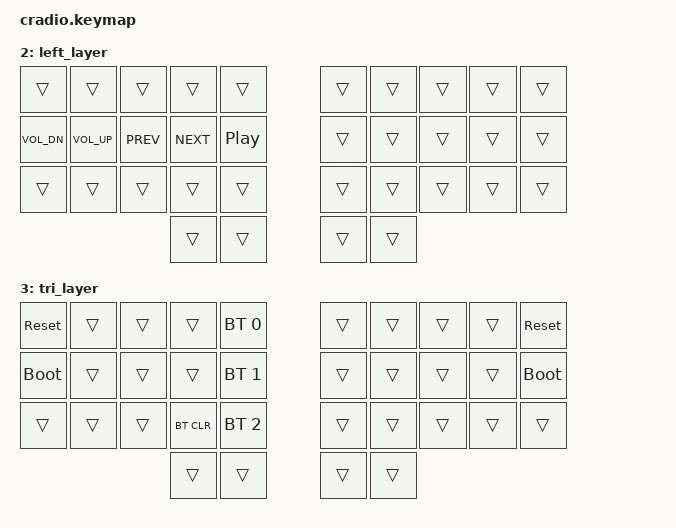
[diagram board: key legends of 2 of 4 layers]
// Copyright (c) 2022 The ZMK Contributors
// SPDX-License-Identifier: MIT

#include <behaviors.dtsi>
#include <dt-bindings/zmk/keys.h>
#include <dt-bindings/zmk/bt.h>

// Home row mods macro
#define HRML(k1,k2,k3,k4) &ht LSHFT k1  &ht LALT k2  &ht LCTRL k3  &ht LGUI k4
#define HRMR(k1,k2,k3,k4) &ht RGUI k1  &ht RCTRL k2  &ht RALT k3  &ht RSHFT k4

/ {
    behaviors {
        ht: hold_tap {
            compatible = "zmk,behavior-hold-tap";
            #binding-cells = <2>;
            flavor = "tap-preferred";
            tapping-term-ms = <200>;
            quick-tap-ms = <150>;
            require-prior-idle-ms = <100>;
            bindings = <&kp>, <&kp>;
        };
        gresc: grave_escape {
            compatible = "zmk,behavior-mod-morph";
            #binding-cells = <0>;
            bindings = <&kp ESC>, <&kp GRAVE>;
            mods = <(MOD_LGUI|MOD_LSFT|MOD_RGUI|MOD_RSFT)>;
            keep-mods = <(MOD_LGUI|MOD_RSFT)>;
        };
    };

    conditional_layers {
        compatible = "zmk,conditional-layers";
        tri_layer {
            if-layers = <1 2>;
            then-layer = <3>;
        };
    };

    keymap {
        compatible = "zmk,keymap";
        default_layer {
            bindings = <
        //╭──────────────┬──────────────┬──────────────┬──────────────┬──────────────╮   ╭──────────────┬──────────────┬──────────────┬──────────────┬──────────────╮
        //│      Q       │      W       │      E       │      R       │      T       │   │      Y       │      U       │      I       │      O       │      P       │
               &kp Q          &kp W          &kp E          &kp R          &kp T              &kp Y          &kp U          &kp I          &kp O          &kp P
        //├──────────────┼──────────────┼──────────────┼──────────────┼──────────────┤   ├──────────────┼──────────────┼──────────────┼──────────────┼──────────────┤
        //│      A       │      S       │      D       │      F       │      G       │   │      H       │      J       │      K       │      L       │       ;      │
            HRML(A,             S,             D,             F)           &kp G              &kp H       HRMR(J,             K,             L,            SEMI)
        //├──────────────┼──────────────┼──────────────┼──────────────┼──────────────┤   ├──────────────┼──────────────┼──────────────┼──────────────┼──────────────┤
        //│      Z       │      X       │      C       │      V       │      B       │   │      N       │      M       │     , <      │     . >      │     / ?      │
               &kp Z          &kp X          &kp C          &kp V         &kp B               &kp N          &kp M         &kp COMMA       &kp DOT       &kp FSLH
        //╰──────────────┴──────────────┴──────────────┼──────────────┼──────────────┤   ├──────────────┼──────────────┼──────────────┴──────────────┴──────────────╯
                                                            &gresc       &lt 1 TAB          &lt 2 SPACE      &kp RET 
        //                                             ╰──────────────┴──────────────╯   ╰──────────────┴──────────────╯
            >;
        };

        right_layer {
            bindings = <
        //╭──────────────┬──────────────┬──────────────┬──────────────┬──────────────╮   ╭──────────────┬──────────────┬──────────────┬──────────────┬──────────────╮
        //│       1      │      2       │       3      │      4       │      5       │   │      6       │       7      │       8      │       9      │      0       │
               &kp N1         &kp N2         &kp N3         &kp N4        &kp N5             &kp N6          &kp N7          &kp N8        &kp N9        &kp N0
        //├──────────────┼──────────────┼──────────────┼──────────────┼──────────────┤   ├──────────────┼──────────────┼──────────────┼──────────────┼──────────────┤
        //│     F2       │    F5        │    F9        │     F10      │    F12       │   │     LEFT     │     DOWN     │      UP      │     RIGHT    │     ' "      │
           HRML(F2,           F5,            F9,             F10)        &kp F12             &kp LEFT       &kp DOWN        &kp UP        &kp RIGHT    &ht RSHFT SQT
        //├──────────────┼──────────────┼──────────────┼──────────────┼──────────────┤   ├──────────────┼──────────────┼──────────────┼──────────────┼──────────────┤
        //│    GRAVE     │  Screenshot  │   Screenshot │     CAPS     │    DEL       │   │       {      │       }      │       -      │       =      │       \      │
             &kp GRAVE    &kp LG(LS(N5)) &kp LG(LS(N4))   &caps_word     &kp DEL             &kp LBKT       &kp RBKT      &kp MINUS        &kp EQUAL      &kp BSLH
        //╰──────────────┴──────────────┴──────────────┼──────────────┼──────────────┤   ├──────────────┼──────────────┼──────────────┴──────────────┴──────────────╯
                                                            &trans         &trans            &kp BSPC        &trans
        //                                             ╰──────────────┴──────────────╯   ╰──────────────┴──────────────╯
            >;
        };

        left_layer {
            bindings = <
        //╭──────────────┬──────────────┬──────────────┬──────────────┬──────────────╮   ╭──────────────┬──────────────┬──────────────┬──────────────┬──────────────╮
        //│              │              │              │              │              │   │              │              │              │              │              │
                &trans       &trans          &trans         &trans         &trans             &trans         &trans          &trans         &trans        &trans
        //├──────────────┼──────────────┼──────────────┼──────────────┼──────────────┤   ├──────────────┼──────────────┼──────────────┼──────────────┼──────────────┤
        //│              │              │              │              │              │   │              │              │              │              │              │
            &kp C_VOL_DN   &kp C_VOL_UP    &kp C_PREV     &kp C_NEXT      &kp C_PP            &trans         &trans          &trans         &trans        &trans
        //├──────────────┼──────────────┼──────────────┼──────────────┼──────────────┤   ├──────────────┼──────────────┼──────────────┼──────────────┼──────────────┤
        //│              │              │              │              │              │   │              │              │              │              │              │
               &trans         &trans         &trans         &trans         &trans             &trans         &trans          &trans         &trans        &trans
        //╰──────────────┴──────────────┴──────────────┼──────────────┼──────────────┤   ├──────────────┼──────────────┼──────────────┴──────────────┴──────────────╯
                                                            &trans         &trans             &trans         &trans
        //                                             ╰──────────────┴──────────────╯   ╰──────────────┴──────────────╯
            >;
        };

        tri_layer {
            bindings = <
        //╭──────────────┬──────────────┬──────────────┬──────────────┬──────────────╮   ╭──────────────┬──────────────┬──────────────┬──────────────┬──────────────╮
        //│     RESET    │              │              │              │  PROFILE 0   │   │              │              │              │              │    RESET     │
             &sys_reset      &trans         &trans         &trans       &bt BT_SEL 0          &trans         &trans         &trans         &trans       &sys_reset
        //├──────────────┼──────────────┼──────────────┼──────────────┼──────────────┤   ├──────────────┼──────────────┼──────────────┼──────────────┼──────────────┤
        //│  BOOTLOADER  │              │              │              │  PROFILE 1   │   │              │              │              │              │  BOOTLOADER  │
             &bootloader     &trans         &trans         &trans       &bt BT_SEL 1          &trans         &trans         &trans         &trans       &bootloader
        //├──────────────┼──────────────┼──────────────┼──────────────┼──────────────┤   ├──────────────┼──────────────┼──────────────┼──────────────┼──────────────┤
        //│              │              │              │   CLEAR BT   │  PROFILE 2   │   │              │              │              │              │              │
               &trans        &trans         &trans         &bt BT_CLR   &bt BT_SEL 2          &trans         &trans         &trans         &trans         &trans
        //╰──────────────┴──────────────┴──────────────┼──────────────┼──────────────┤   ├──────────────┼──────────────┼──────────────┴──────────────┴──────────────╯
                                                            &trans        &trans              &trans         &trans
        //                                             ╰──────────────┴──────────────╯   ╰──────────────┴──────────────╯
            >;
        };
    };
};
